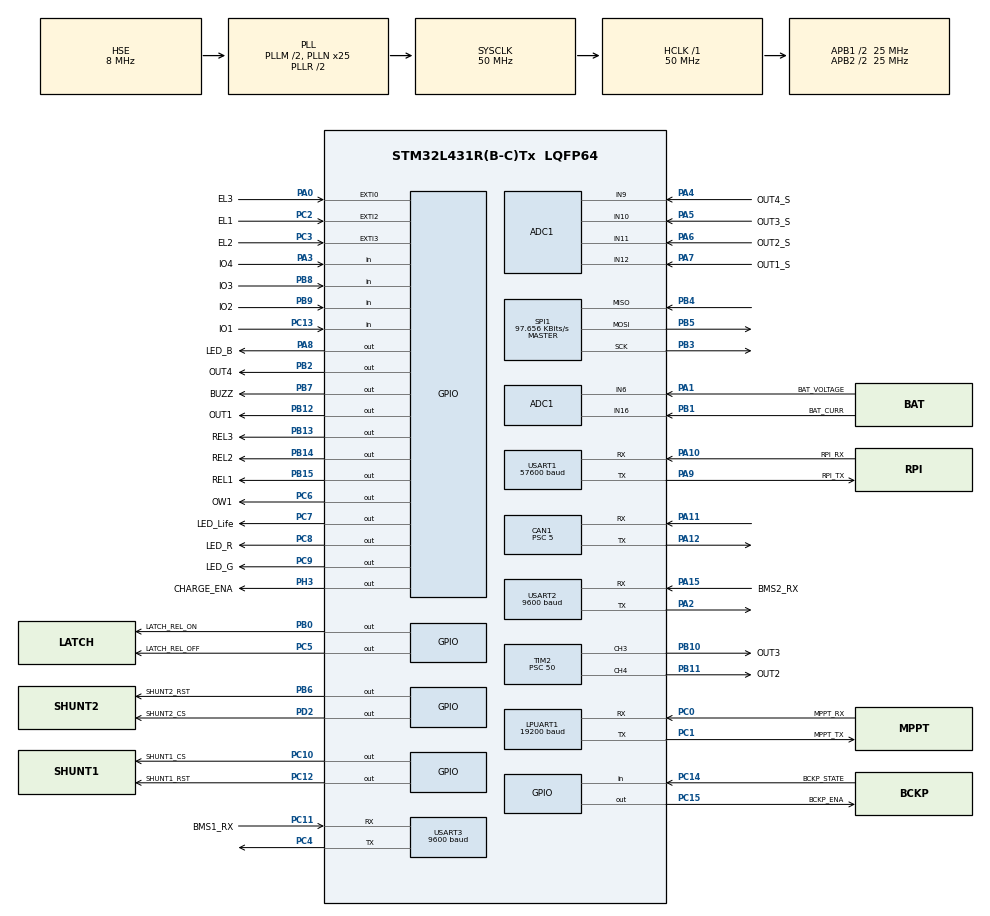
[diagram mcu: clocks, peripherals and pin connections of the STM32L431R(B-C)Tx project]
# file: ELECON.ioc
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ADC1.Channel-0\#ChannelRegularConversion=ADC_CHANNEL_6
ADC1.Channel-1\#ChannelRegularConversion=ADC_CHANNEL_9
ADC1.Channel-2\#ChannelRegularConversion=ADC_CHANNEL_10
ADC1.Channel-3\#ChannelRegularConversion=ADC_CHANNEL_11
ADC1.Channel-4\#ChannelRegularConversion=ADC_CHANNEL_12
ADC1.Channel-5\#ChannelRegularConversion=ADC_CHANNEL_16
ADC1.ContinuousConvMode=ENABLE
ADC1.DMAContinuousRequests=ENABLE
ADC1.EOCSelection=ADC_EOC_SINGLE_CONV
ADC1.NbrOfConversion=6
ADC1.NbrOfConversionFlag=1
ADC1.OffsetNumber-0\#ChannelRegularConversion=ADC_OFFSET_NONE
ADC1.OffsetNumber-1\#ChannelRegularConversion=ADC_OFFSET_NONE
ADC1.OffsetNumber-2\#ChannelRegularConversion=ADC_OFFSET_NONE
ADC1.OffsetNumber-3\#ChannelRegularConversion=ADC_OFFSET_NONE
ADC1.OffsetNumber-4\#ChannelRegularConversion=ADC_OFFSET_NONE
ADC1.OffsetNumber-5\#ChannelRegularConversion=ADC_OFFSET_NONE
ADC1.Rank-0\#ChannelRegularConversion=1
ADC1.Rank-1\#ChannelRegularConversion=2
ADC1.Rank-2\#ChannelRegularConversion=3
ADC1.Rank-3\#ChannelRegularConversion=4
ADC1.Rank-4\#ChannelRegularConversion=5
ADC1.Rank-5\#ChannelRegularConversion=6
ADC1.SamplingTime-0\#ChannelRegularConversion=ADC_SAMPLETIME_2CYCLES_5
ADC1.SamplingTime-1\#ChannelRegularConversion=ADC_SAMPLETIME_2CYCLES_5
ADC1.SamplingTime-2\#ChannelRegularConversion=ADC_SAMPLETIME_2CYCLES_5
ADC1.SamplingTime-3\#ChannelRegularConversion=ADC_SAMPLETIME_2CYCLES_5
ADC1.SamplingTime-4\#ChannelRegularConversion=ADC_SAMPLETIME_2CYCLES_5
ADC1.SamplingTime-5\#ChannelRegularConversion=ADC_SAMPLETIME_2CYCLES_5
ADC1.master=1
CAN1.ABOM=ENABLE
CAN1.BS1=CAN_BS1_15TQ
CAN1.BS2=CAN_BS2_4TQ
CAN1.CalculateBaudRate=250000
CAN1.CalculateTimeBit=4000
CAN1.CalculateTimeQuantum=200.0
CAN1.NART=ENABLE
CAN1.Prescaler=5
Dma.ADC1.2.Direction=DMA_PERIPH_TO_MEMORY
Dma.ADC1.2.Instance=DMA1_Channel1
Dma.ADC1.2.MemDataAlignment=DMA_MDATAALIGN_HALFWORD
Dma.ADC1.2.MemInc=DMA_MINC_ENABLE
Dma.ADC1.2.Mode=DMA_NORMAL
Dma.ADC1.2.PeriphDataAlignment=DMA_PDATAALIGN_HALFWORD
Dma.ADC1.2.PeriphInc=DMA_PINC_DISABLE
Dma.ADC1.2.Priority=DMA_PRIORITY_LOW
Dma.LPUART_RX.5.Direction=DMA_PERIPH_TO_MEMORY
Dma.LPUART_RX.5.Instance=DMA2_Channel7
Dma.LPUART_RX.5.MemDataAlignment=DMA_MDATAALIGN_BYTE
Dma.LPUART_RX.5.MemInc=DMA_MINC_ENABLE
Dma.LPUART_RX.5.Mode=DMA_NORMAL
Dma.LPUART_RX.5.PeriphDataAlignment=DMA_PDATAALIGN_BYTE
Dma.LPUART_RX.5.PeriphInc=DMA_PINC_DISABLE
Dma.LPUART_RX.5.Priority=DMA_PRIORITY_LOW
Dma.LPUART_TX.6.Direction=DMA_MEMORY_TO_PERIPH
Dma.LPUART_TX.6.Instance=DMA2_Channel6
Dma.LPUART_TX.6.MemDataAlignment=DMA_MDATAALIGN_BYTE
Dma.LPUART_TX.6.MemInc=DMA_MINC_ENABLE
Dma.LPUART_TX.6.Mode=DMA_NORMAL
Dma.LPUART_TX.6.PeriphDataAlignment=DMA_PDATAALIGN_BYTE
Dma.LPUART_TX.6.PeriphInc=DMA_PINC_DISABLE
Dma.LPUART_TX.6.Priority=DMA_PRIORITY_LOW
Dma.Request0=USART1_RX
Dma.Request1=USART1_TX
Dma.Request2=ADC1
Dma.Request3=USART3_RX
Dma.Request4=USART2_RX
Dma.Request5=LPUART_RX
Dma.Request6=LPUART_TX
Dma.Request7=SPI1_RX
Dma.Request8=SPI1_TX
Dma.SPI1_RX.7.Direction=DMA_PERIPH_TO_MEMORY
Dma.SPI1_RX.7.Instance=DMA1_Channel2
Dma.SPI1_RX.7.MemDataAlignment=DMA_MDATAALIGN_BYTE
Dma.SPI1_RX.7.MemInc=DMA_MINC_ENABLE
Dma.SPI1_RX.7.Mode=DMA_NORMAL
Dma.SPI1_RX.7.PeriphDataAlignment=DMA_PDATAALIGN_BYTE
Dma.SPI1_RX.7.PeriphInc=DMA_PINC_DISABLE
Dma.SPI1_RX.7.Priority=DMA_PRIORITY_LOW
Dma.SPI1_TX.8.Direction=DMA_MEMORY_TO_PERIPH
Dma.SPI1_TX.8.Instance=DMA2_Channel4
Dma.SPI1_TX.8.MemDataAlignment=DMA_MDATAALIGN_BYTE
Dma.SPI1_TX.8.MemInc=DMA_MINC_ENABLE
Dma.SPI1_TX.8.Mode=DMA_NORMAL
Dma.SPI1_TX.8.PeriphDataAlignment=DMA_PDATAALIGN_BYTE
Dma.SPI1_TX.8.PeriphInc=DMA_PINC_DISABLE
Dma.SPI1_TX.8.Priority=DMA_PRIORITY_LOW
Dma.USART1_RX.0.Direction=DMA_PERIPH_TO_MEMORY
Dma.USART1_RX.0.Instance=DMA1_Channel5
Dma.USART1_RX.0.MemDataAlignment=DMA_MDATAALIGN_BYTE
Dma.USART1_RX.0.MemInc=DMA_MINC_ENABLE
Dma.USART1_RX.0.Mode=DMA_NORMAL
Dma.USART1_RX.0.PeriphDataAlignment=DMA_PDATAALIGN_BYTE
Dma.USART1_RX.0.PeriphInc=DMA_PINC_DISABLE
Dma.USART1_RX.0.Priority=DMA_PRIORITY_LOW
Dma.USART1_TX.1.Direction=DMA_MEMORY_TO_PERIPH
Dma.USART1_TX.1.Instance=DMA1_Channel4
Dma.USART1_TX.1.MemDataAlignment=DMA_MDATAALIGN_BYTE
Dma.USART1_TX.1.MemInc=DMA_MINC_ENABLE
Dma.USART1_TX.1.Mode=DMA_NORMAL
Dma.USART1_TX.1.PeriphDataAlignment=DMA_PDATAALIGN_BYTE
Dma.USART1_TX.1.PeriphInc=DMA_PINC_DISABLE
Dma.USART1_TX.1.Priority=DMA_PRIORITY_LOW
Dma.USART2_RX.4.Direction=DMA_PERIPH_TO_MEMORY
Dma.USART2_RX.4.Instance=DMA1_Channel6
Dma.USART2_RX.4.MemDataAlignment=DMA_MDATAALIGN_BYTE
Dma.USART2_RX.4.MemInc=DMA_MINC_ENABLE
Dma.USART2_RX.4.Mode=DMA_NORMAL
Dma.USART2_RX.4.PeriphDataAlignment=DMA_PDATAALIGN_BYTE
Dma.USART2_RX.4.PeriphInc=DMA_PINC_DISABLE
Dma.USART2_RX.4.Priority=DMA_PRIORITY_LOW
Dma.USART3_RX.3.Direction=DMA_PERIPH_TO_MEMORY
Dma.USART3_RX.3.Instance=DMA1_Channel3
Dma.USART3_RX.3.MemDataAlignment=DMA_MDATAALIGN_BYTE
Dma.USART3_RX.3.MemInc=DMA_MINC_ENABLE
Dma.USART3_RX.3.Mode=DMA_NORMAL
Dma.USART3_RX.3.PeriphDataAlignment=DMA_PDATAALIGN_BYTE
Dma.USART3_RX.3.PeriphInc=DMA_PINC_DISABLE
Dma.USART3_RX.3.Priority=DMA_PRIORITY_LOW
IWDG.Prescaler=IWDG_PRESCALER_256
IWDG.Reload=375
LPUART1.BaudRate=19200
LPUART1.OverrunDisableParam=UART_ADVFEATURE_OVERRUN_DISABLE
LPUART1.WordLength=UART_WORDLENGTH_8B
Mcu.Family=STM32L4
Mcu.Name=STM32L431R(B-C)Tx
Mcu.Package=LQFP64
NVIC.ADC1_IRQn=true\:2\:0\:true\:false\:true\:true\:true\:true
NVIC.CAN1_RX0_IRQn=true\:1\:0\:true\:false\:true\:true\:true\:true
NVIC.CAN1_RX1_IRQn=true\:1\:0\:true\:false\:true\:true\:true\:true
NVIC.CAN1_TX_IRQn=true\:2\:0\:true\:false\:true\:true\:true\:true
NVIC.DMA1_Channel1_IRQn=true\:2\:0\:true\:false\:true\:false\:true\:true
NVIC.DMA1_Channel2_IRQn=true\:1\:0\:true\:false\:true\:false\:true\:true
NVIC.DMA1_Channel3_IRQn=true\:4\:0\:true\:false\:true\:false\:true\:true
NVIC.DMA1_Channel4_IRQn=true\:2\:0\:true\:false\:true\:false\:true\:true
NVIC.DMA1_Channel5_IRQn=true\:2\:0\:true\:false\:true\:false\:true\:true
NVIC.DMA1_Channel6_IRQn=true\:4\:0\:true\:false\:true\:false\:true\:true
NVIC.DMA2_Channel4_IRQn=true\:1\:0\:true\:false\:true\:false\:true\:true
NVIC.DMA2_Channel6_IRQn=true\:2\:0\:true\:false\:true\:false\:true\:true
NVIC.DMA2_Channel7_IRQn=true\:2\:0\:true\:false\:true\:false\:true\:true
NVIC.EXTI0_IRQn=true\:6\:0\:true\:false\:true\:true\:true\:true
NVIC.EXTI2_IRQn=true\:6\:0\:true\:false\:true\:true\:true\:true
NVIC.EXTI3_IRQn=true\:6\:0\:true\:false\:true\:true\:true\:true
NVIC.LPUART1_IRQn=true\:2\:0\:true\:false\:true\:true\:true\:true
NVIC.PriorityGroup=NVIC_PRIORITYGROUP_4
NVIC.SPI1_IRQn=true\:1\:0\:true\:false\:true\:true\:true\:true
NVIC.TIM6_DAC_IRQn=true\:0\:0\:false\:false\:true\:true\:true\:true
NVIC.USART1_IRQn=true\:2\:0\:true\:false\:true\:true\:true\:true
NVIC.USART2_IRQn=true\:3\:0\:true\:false\:true\:true\:true\:true
NVIC.USART3_IRQn=true\:3\:0\:true\:false\:true\:true\:true\:true
PA0.GPIO_Label=EL3
PA0.Signal=GPXTI0
PA1.GPIO_Label=BAT_VOLTAGE
PA1.Signal=ADCx_IN6
PA10.GPIO_Label=RPI_RX
PA10.Mode=Asynchronous
PA10.Signal=USART1_RX
PA11.Mode=CAN_Activate
PA11.Signal=CAN1_RX
PA12.Mode=CAN_Activate
PA12.Signal=CAN1_TX
PA13\ (JTMS-SWDIO).Mode=Serial_Wire
PA13\ (JTMS-SWDIO).Signal=SYS_JTMS-SWDIO
PA14\ (JTCK-SWCLK).Mode=Serial_Wire
PA14\ (JTCK-SWCLK).Signal=SYS_JTCK-SWCLK
PA15\ (JTDI).GPIO_Label=BMS2_RX
PA15\ (JTDI).Mode=Asynchronous
PA15\ (JTDI).Signal=USART2_RX
PA2.Mode=Asynchronous
PA2.Signal=USART2_TX
PA3.GPIO_Label=IO4
PA3.Signal=GPIO_Input
PA4.GPIO_Label=OUT4_S
PA4.Signal=ADCx_IN9
PA5.GPIO_Label=OUT3_S
PA5.Signal=ADCx_IN10
PA6.GPIO_Label=OUT2_S
PA6.Signal=ADCx_IN11
PA7.GPIO_Label=OUT1_S
PA7.Signal=ADCx_IN12
PA8.GPIO_Label=LED_B
PA8.Signal=GPIO_Output
PA9.GPIO_Label=RPI_TX
PA9.Mode=Asynchronous
PA9.Signal=USART1_TX
PB0.GPIO_Label=LATCH_REL_ON
PB0.Signal=GPIO_Output
PB1.GPIO_Label=BAT_CURR
PB1.Signal=ADCx_IN16
PB10.GPIO_Label=OUT3
PB10.Signal=S_TIM2_CH3
PB11.GPIO_Label=OUT2
PB11.Signal=S_TIM2_CH4
PB12.GPIO_Label=OUT1
PB12.Signal=GPIO_Output
PB13.GPIO_Label=REL3
PB13.Signal=GPIO_Output
PB14.GPIO_Label=REL2
PB14.Signal=GPIO_Output
PB15.GPIO_Label=REL1
PB15.Signal=GPIO_Output
PB2.GPIO_Label=OUT4
PB2.Signal=GPIO_Output
PB3\ (JTDO-TRACESWO).Mode=Full_Duplex_Master
PB3\ (JTDO-TRACESWO).Signal=SPI1_SCK
PB4\ (NJTRST).Mode=Full_Duplex_Master
PB4\ (NJTRST).Signal=SPI1_MISO
PB5.Mode=Full_Duplex_Master
PB5.Signal=SPI1_MOSI
PB6.GPIO_Label=SHUNT2_RST
PB6.Signal=GPIO_Output
PB7.GPIO_Label=BUZZ
PB7.Signal=GPIO_Output
PB8.GPIO_Label=IO3
PB8.Signal=GPIO_Input
PB9.GPIO_Label=IO2
PB9.Signal=GPIO_Input
PC0.GPIO_Label=MPPT_RX
PC0.Mode=Asynchronous
PC0.Signal=LPUART1_RX
PC1.GPIO_Label=MPPT_TX
PC1.Mode=Asynchronous
PC1.Signal=LPUART1_TX
PC10.GPIO_Label=SHUNT1_CS
PC10.Signal=GPIO_Output
PC11.GPIO_Label=BMS1_RX
PC11.Mode=Asynchronous
PC11.Signal=USART3_RX
PC12.GPIO_Label=SHUNT1_RST
PC12.Signal=GPIO_Output
PC13.GPIO_Label=IO1
PC13.Signal=GPIO_Input
PC14-OSC32_IN\ (PC14).GPIO_Label=BCKP_STATE
PC14-OSC32_IN\ (PC14).GPIO_PuPd=GPIO_PULLDOWN
PC14-OSC32_IN\ (PC14).Signal=GPIO_Input
PC15-OSC32_OUT\ (PC15).GPIO_Label=BCKP_ENA
PC15-OSC32_OUT\ (PC15).Signal=GPIO_Output
PC2.GPIO_Label=EL1
PC2.Signal=GPXTI2
PC3.GPIO_Label=EL2
PC3.Signal=GPXTI3
PC4.Mode=Asynchronous
PC4.Signal=USART3_TX
PC5.GPIO_Label=LATCH_REL_OFF
PC5.Signal=GPIO_Output
PC6.GPIO_Label=OW1
PC6.GPIO_ModeDefaultOutputPP=GPIO_MODE_OUTPUT_OD
PC6.Signal=GPIO_Output
PC7.GPIO_Label=LED_Life
PC7.Signal=GPIO_Output
PC8.GPIO_Label=LED_R
PC8.Signal=GPIO_Output
PC9.GPIO_Label=LED_G
PC9.Signal=GPIO_Output
PD2.GPIO_Label=SHUNT2_CS
PD2.Signal=GPIO_Output
PH0-OSC_IN\ (PH0).Mode=HSE-External-Oscillator
PH0-OSC_IN\ (PH0).Signal=RCC_OSC_IN
PH1-OSC_OUT\ (PH1).Mode=HSE-External-Oscillator
PH1-OSC_OUT\ (PH1).Signal=RCC_OSC_OUT
PH3-BOOT0.GPIO_Label=CHARGE_ENA
PH3-BOOT0.Signal=GPIO_Output
ProjectManager.HeapSize=0x2000
ProjectManager.StackSize=0x400
ProjectManager.TargetToolchain=STM32CubeIDE
RCC.ADCCLockSelection=RCC_ADCCLKSOURCE_SYSCLK
RCC.ADCFreq_Value=50000000
RCC.AHBFreq_Value=50000000
RCC.APB1CLKDivider=RCC_HCLK_DIV2
RCC.APB1Freq_Value=25000000
RCC.APB1TimFreq_Value=50000000
RCC.APB2CLKDivider=RCC_HCLK_DIV2
RCC.APB2Freq_Value=25000000
RCC.APB2TimFreq_Value=50000000
RCC.CortexFreq_Value=50000000
RCC.HCLKFreq_Value=50000000
RCC.HSE_VALUE=8000000
RCC.HSI48_VALUE=48000000
RCC.HSI_VALUE=16000000
RCC.LSE_VALUE=32768
RCC.MSI_VALUE=4000000
RCC.PLLM=2
RCC.PLLN=25
RCC.PLLSAI1N=26
RCC.PLLSourceVirtual=RCC_PLLSOURCE_HSE
RCC.RTCClockSelection=RCC_RTCCLKSOURCE_HSE_DIV32
RCC.SYSCLKFreq_VALUE=50000000
RCC.SYSCLKSource=RCC_SYSCLKSOURCE_PLLCLK
RCC.VCOOutputFreq_Value=100000000
RTC.AsynchPrediv=124
RTC.SynchPrediv=1999
SH.ADCx_IN10.0=ADC1_IN10,IN10-Single-Ended
SH.ADCx_IN11.0=ADC1_IN11,IN11-Single-Ended
SH.ADCx_IN12.0=ADC1_IN12,IN12-Single-Ended
SH.ADCx_IN16.0=ADC1_IN16,IN16-Single-Ended
SH.ADCx_IN6.0=ADC1_IN6,IN6-Single-Ended
SH.ADCx_IN9.0=ADC1_IN9,IN9-Single-Ended
SH.S_TIM2_CH3.0=TIM2_CH3,PWM Generation3 CH3
SH.S_TIM2_CH4.0=TIM2_CH4,PWM Generation4 CH4
SPI1.BaudRatePrescaler=SPI_BAUDRATEPRESCALER_256
SPI1.CLKPhase=SPI_PHASE_2EDGE
SPI1.CalculateBaudRate=97.656 KBits/s
SPI1.DataSize=SPI_DATASIZE_8BIT
SPI1.Direction=SPI_DIRECTION_2LINES
SPI1.Mode=SPI_MODE_MASTER
SPI1.VirtualType=VM_MASTER
TIM2.Channel-PWM\ Generation3\ CH3=TIM_CHANNEL_3
TIM2.Channel-PWM\ Generation4\ CH4=TIM_CHANNEL_4
TIM2.Period=1000
TIM2.Prescaler=50
TIM6.Period=1000
TIM6.Prescaler=4
USART1.BaudRate=57600
USART1.VirtualMode-Asynchronous=VM_ASYNC
USART2.BaudRate=9600
USART2.Mode=MODE_RX
USART2.OverrunDisableParam=ADVFEATURE_OVERRUN_DISABLE
USART2.VirtualMode-Asynchronous=VM_ASYNC
USART3.BaudRate=9600
USART3.Mode=MODE_RX
USART3.OverrunDisableParam=ADVFEATURE_OVERRUN_DISABLE
USART3.VirtualMode-Asynchronous=VM_ASYNC
VP_IWDG_VS_IWDG.Mode=IWDG_Activate
VP_RTC_VS_RTC_Activate.Mode=RTC_Enabled
VP_TIM2_VS_ClockSourceINT.Mode=Internal
VP_TIM6_VS_ClockSourceINT.Mode=Enable_Timer
board=custom

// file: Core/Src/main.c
/* USER CODE BEGIN Header */
/**
  ******************************************************************************
  * @file           : main.c
  * @brief          : Main program body
  ******************************************************************************
  * @attention
  *
  * <h2><center>&copy; Copyright (c) 2021 STMicroelectronics.
  * All rights reserved.</center></h2>
  *
  * This software component is licensed by ST under BSD 3-Clause license,
  * the "License"; You may not use this file except in compliance with the
  * License. You may obtain a copy of the License at:
  *                        opensource.org/licenses/BSD-3-Clause
  *
  ******************************************************************************
  */
/* USER CODE END Header */
#include "main.h"

/* USER CODE BEGIN Includes */
#include "APP.h"
#include "MEMORY_MAP.h"
/* USER CODE END Includes */

 ADC_HandleTypeDef hadc1;
DMA_HandleTypeDef hdma_adc1;

CAN_HandleTypeDef hcan1;

IWDG_HandleTypeDef hiwdg;

UART_HandleTypeDef hlpuart1;
UART_HandleTypeDef huart1;
UART_HandleTypeDef huart2;
UART_HandleTypeDef huart3;
DMA_HandleTypeDef hdma_lpuart_rx;
DMA_HandleTypeDef hdma_lpuart_tx;
DMA_HandleTypeDef hdma_usart1_rx;
DMA_HandleTypeDef hdma_usart1_tx;
DMA_HandleTypeDef hdma_usart2_rx;
DMA_HandleTypeDef hdma_usart3_rx;

RTC_HandleTypeDef hrtc;

SPI_HandleTypeDef hspi1;
DMA_HandleTypeDef hdma_spi1_rx;
DMA_HandleTypeDef hdma_spi1_tx;

TIM_HandleTypeDef htim2;
TIM_HandleTypeDef htim6;

void SystemClock_Config(void);
static void MX_GPIO_Init(void);
static void MX_DMA_Init(void);
static void MX_CAN1_Init(void);
static void MX_USART1_UART_Init(void);
static void MX_TIM6_Init(void);
static void MX_ADC1_Init(void);
static void MX_RTC_Init(void);
static void MX_IWDG_Init(void);
static void MX_LPUART1_UART_Init(void);
static void MX_USART2_UART_Init(void);
static void MX_USART3_UART_Init(void);
static void MX_SPI1_Init(void);
static void MX_TIM2_Init(void);

int main(void)
{
  /* USER CODE BEGIN 1 */
  SCB->VTOR = ADDRESS_OF_DEFAULT_APP_START;
  __DSB();
  __ISB();
  __enable_irq();   // clears PRIMASK

  /* USER CODE END 1 */

  /* MCU Configuration--------------------------------------------------------*/

  /* Reset of all peripherals, Initializes the Flash interface and the Systick. */
  HAL_Init();

  /* Configure the system clock */
  SystemClock_Config();

  /* Initialize all configured peripherals */
  MX_GPIO_Init();
  MX_DMA_Init();
  MX_CAN1_Init();
  MX_USART1_UART_Init();
  MX_TIM6_Init();
  MX_ADC1_Init();
  MX_RTC_Init();
  MX_IWDG_Init();
  MX_LPUART1_UART_Init();
  MX_USART2_UART_Init();
  MX_USART3_UART_Init();
  MX_SPI1_Init();
  MX_TIM2_Init();

  /* Infinite loop */
  /* USER CODE BEGIN WHILE */

  APP_Init();
  APP_Start();

  while (1)
  {
    /* USER CODE END WHILE */

  }
}

void SystemClock_Config(void)
{
  RCC_OscInitTypeDef RCC_OscInitStruct = {0};
  RCC_ClkInitTypeDef RCC_ClkInitStruct = {0};

  /** Configure the main internal regulator output voltage
  */
  if (HAL_PWREx_ControlVoltageScaling(PWR_REGULATOR_VOLTAGE_SCALE1) != HAL_OK)
  {
    Error_Handler();
  }

  /** Initializes the RCC Oscillators according to the specified parameters
  * in the RCC_OscInitTypeDef structure.
  */
  RCC_OscInitStruct.OscillatorType = RCC_OSCILLATORTYPE_LSI|RCC_OSCILLATORTYPE_HSE;
  RCC_OscInitStruct.HSEState = RCC_HSE_ON;
  RCC_OscInitStruct.LSIState = RCC_LSI_ON;
  RCC_OscInitStruct.PLL.PLLState = RCC_PLL_ON;
  RCC_OscInitStruct.PLL.PLLSource = RCC_PLLSOURCE_HSE;
  RCC_OscInitStruct.PLL.PLLM = 2;
  RCC_OscInitStruct.PLL.PLLN = 25;
  RCC_OscInitStruct.PLL.PLLP = RCC_PLLP_DIV7;
  RCC_OscInitStruct.PLL.PLLQ = RCC_PLLQ_DIV2;
  RCC_OscInitStruct.PLL.PLLR = RCC_PLLR_DIV2;
  if (HAL_RCC_OscConfig(&RCC_OscInitStruct) != HAL_OK)
  {
    Error_Handler();
  }

  /** Initializes the CPU, AHB and APB buses clocks
  */
  RCC_ClkInitStruct.ClockType = RCC_CLOCKTYPE_HCLK|RCC_CLOCKTYPE_SYSCLK
                              |RCC_CLOCKTYPE_PCLK1|RCC_CLOCKTYPE_PCLK2;
  RCC_ClkInitStruct.SYSCLKSource = RCC_SYSCLKSOURCE_PLLCLK;
  RCC_ClkInitStruct.AHBCLKDivider = RCC_SYSCLK_DIV1;
  RCC_ClkInitStruct.APB1CLKDivider = RCC_HCLK_DIV2;
  RCC_ClkInitStruct.APB2CLKDivider = RCC_HCLK_DIV2;

  if (HAL_RCC_ClockConfig(&RCC_ClkInitStruct, FLASH_LATENCY_3) != HAL_OK)
  {
    Error_Handler();
  }
}

static void MX_ADC1_Init(void)
{

  ADC_ChannelConfTypeDef sConfig = {0};

  /** Common config
  */
  hadc1.Instance = ADC1;
  hadc1.Init.ClockPrescaler = ADC_CLOCK_ASYNC_DIV1;
  hadc1.Init.Resolution = ADC_RESOLUTION_12B;
  hadc1.Init.DataAlign = ADC_DATAALIGN_RIGHT;
  hadc1.Init.ScanConvMode = ADC_SCAN_ENABLE;
  hadc1.Init.EOCSelection = ADC_EOC_SINGLE_CONV;
  hadc1.Init.LowPowerAutoWait = DISABLE;
  hadc1.Init.ContinuousConvMode = ENABLE;
  hadc1.Init.NbrOfConversion = 6;
  hadc1.Init.DiscontinuousConvMode = DISABLE;
  hadc1.Init.ExternalTrigConv = ADC_SOFTWARE_START;
  hadc1.Init.ExternalTrigConvEdge = ADC_EXTERNALTRIGCONVEDGE_NONE;
  hadc1.Init.DMAContinuousRequests = ENABLE;
  hadc1.Init.Overrun = ADC_OVR_DATA_PRESERVED;
  hadc1.Init.OversamplingMode = DISABLE;
  if (HAL_ADC_Init(&hadc1) != HAL_OK)
  {
    Error_Handler();
  }

  /** Configure Regular Channel
  */
  sConfig.Channel = ADC_CHANNEL_6;
  sConfig.Rank = ADC_REGULAR_RANK_1;
  sConfig.SamplingTime = ADC_SAMPLETIME_2CYCLES_5;
  sConfig.SingleDiff = ADC_SINGLE_ENDED;
  sConfig.OffsetNumber = ADC_OFFSET_NONE;
  sConfig.Offset = 0;
  if (HAL_ADC_ConfigChannel(&hadc1, &sConfig) != HAL_OK)
  {
    Error_Handler();
  }

  /** Configure Regular Channel
  */
  sConfig.Channel = ADC_CHANNEL_9;
  sConfig.Rank = ADC_REGULAR_RANK_2;
  if (HAL_ADC_ConfigChannel(&hadc1, &sConfig) != HAL_OK)
  {
    Error_Handler();
  }

  /** Configure Regular Channel
  */
  sConfig.Channel = ADC_CHANNEL_10;
  sConfig.Rank = ADC_REGULAR_RANK_3;
  if (HAL_ADC_ConfigChannel(&hadc1, &sConfig) != HAL_OK)
  {
    Error_Handler();
  }

  /** Configure Regular Channel
  */
  sConfig.Channel = ADC_CHANNEL_11;
  sConfig.Rank = ADC_REGULAR_RANK_4;
  if (HAL_ADC_ConfigChannel(&hadc1, &sConfig) != HAL_OK)
  {
    Error_Handler();
  }

  /** Configure Regular Channel
  */
  sConfig.Channel = ADC_CHANNEL_12;
  sConfig.Rank = ADC_REGULAR_RANK_5;
  if (HAL_ADC_ConfigChannel(&hadc1, &sConfig) != HAL_OK)
  {
    Error_Handler();
  }

  /** Configure Regular Channel
  */
  sConfig.Channel = ADC_CHANNEL_16;
  sConfig.Rank = ADC_REGULAR_RANK_6;
  if (HAL_ADC_ConfigChannel(&hadc1, &sConfig) != HAL_OK)
  {
    Error_Handler();
  }

}

static void MX_CAN1_Init(void)
{

  hcan1.Instance = CAN1;
  hcan1.Init.Prescaler = 5;
  hcan1.Init.Mode = CAN_MODE_NORMAL;
  hcan1.Init.SyncJumpWidth = CAN_SJW_1TQ;
  hcan1.Init.TimeSeg1 = CAN_BS1_15TQ;
  hcan1.Init.TimeSeg2 = CAN_BS2_4TQ;
  hcan1.Init.TimeTriggeredMode = DISABLE;
  hcan1.Init.AutoBusOff = ENABLE;
  hcan1.Init.AutoWakeUp = DISABLE;
  hcan1.Init.AutoRetransmission = ENABLE;
  hcan1.Init.ReceiveFifoLocked = DISABLE;
  hcan1.Init.TransmitFifoPriority = DISABLE;
  if (HAL_CAN_Init(&hcan1) != HAL_OK)
  {
    Error_Handler();
  }

}

static void MX_IWDG_Init(void)
{

  hiwdg.Instance = IWDG;
  hiwdg.Init.Prescaler = IWDG_PRESCALER_256;
  hiwdg.Init.Window = 4095;
  hiwdg.Init.Reload = 375;
  if (HAL_IWDG_Init(&hiwdg) != HAL_OK)
  {
    Error_Handler();
  }

}

static void MX_LPUART1_UART_Init(void)
{

  hlpuart1.Instance = LPUART1;
  hlpuart1.Init.BaudRate = 19200;
  hlpuart1.Init.WordLength = UART_WORDLENGTH_8B;
  hlpuart1.Init.StopBits = UART_STOPBITS_1;
  hlpuart1.Init.Parity = UART_PARITY_NONE;
  hlpuart1.Init.Mode = UART_MODE_TX_RX;
  hlpuart1.Init.HwFlowCtl = UART_HWCONTROL_NONE;
  hlpuart1.Init.OneBitSampling = UART_ONE_BIT_SAMPLE_DISABLE;
  hlpuart1.AdvancedInit.AdvFeatureInit = UART_ADVFEATURE_RXOVERRUNDISABLE_INIT;
  hlpuart1.AdvancedInit.OverrunDisable = UART_ADVFEATURE_OVERRUN_DISABLE;
  if (HAL_UART_Init(&hlpuart1) != HAL_OK)
  {
    Error_Handler();
  }

}

static void MX_USART1_UART_Init(void)
{

  huart1.Instance = USART1;
  huart1.Init.BaudRate = 115200;
  huart1.Init.WordLength = UART_WORDLENGTH_8B;
  huart1.Init.StopBits = UART_STOPBITS_1;
  huart1.Init.Parity = UART_PARITY_NONE;
  huart1.Init.Mode = UART_MODE_TX_RX;
  huart1.Init.HwFlowCtl = UART_HWCONTROL_NONE;
  huart1.Init.OverSampling = UART_OVERSAMPLING_16;
  huart1.Init.OneBitSampling = UART_ONE_BIT_SAMPLE_DISABLE;
  huart1.AdvancedInit.AdvFeatureInit = UART_ADVFEATURE_NO_INIT;
  if (HAL_UART_Init(&huart1) != HAL_OK)
  {
    Error_Handler();
  }

}

static void MX_USART2_UART_Init(void)
{

  huart2.Instance = USART2;
  huart2.Init.BaudRate = 9600;
  huart2.Init.WordLength = UART_WORDLENGTH_8B;
  huart2.Init.StopBits = UART_STOPBITS_1;
  huart2.Init.Parity = UART_PARITY_NONE;
  huart2.Init.Mode = UART_MODE_RX;
  huart2.Init.HwFlowCtl = UART_HWCONTROL_NONE;
  huart2.Init.OverSampling = UART_OVERSAMPLING_16;
  huart2.Init.OneBitSampling = UART_ONE_BIT_SAMPLE_DISABLE;
  huart2.AdvancedInit.AdvFeatureInit = UART_ADVFEATURE_RXOVERRUNDISABLE_INIT;
  huart2.AdvancedInit.OverrunDisable = UART_ADVFEATURE_OVERRUN_DISABLE;
  if (HAL_UART_Init(&huart2) != HAL_OK)
  {
    Error_Handler();
  }

}

static void MX_USART3_UART_Init(void)
{

  huart3.Instance = USART3;
  huart3.Init.BaudRate = 9600;
  huart3.Init.WordLength = UART_WORDLENGTH_8B;
  huart3.Init.StopBits = UART_STOPBITS_1;
  huart3.Init.Parity = UART_PARITY_NONE;
  huart3.Init.Mode = UART_MODE_RX;
  huart3.Init.HwFlowCtl = UART_HWCONTROL_NONE;
  huart3.Init.OverSampling = UART_OVERSAMPLING_16;
  huart3.Init.OneBitSampling = UART_ONE_BIT_SAMPLE_DISABLE;
  huart3.AdvancedInit.AdvFeatureInit = UART_ADVFEATURE_RXOVERRUNDISABLE_INIT;
  huart3.AdvancedInit.OverrunDisable = UART_ADVFEATURE_OVERRUN_DISABLE;
  if (HAL_UART_Init(&huart3) != HAL_OK)
  {
    Error_Handler();
  }

}

static void MX_RTC_Init(void)
{

  /** Initialize RTC Only
  */
  hrtc.Instance = RTC;
  hrtc.Init.HourFormat = RTC_HOURFORMAT_24;
  hrtc.Init.AsynchPrediv = 124;
  hrtc.Init.SynchPrediv = 1999;
  hrtc.Init.OutPut = RTC_OUTPUT_DISABLE;
  hrtc.Init.OutPutRemap = RTC_OUTPUT_REMAP_NONE;
  hrtc.Init.OutPutPolarity = RTC_OUTPUT_POLARITY_HIGH;
  hrtc.Init.OutPutType = RTC_OUTPUT_TYPE_OPENDRAIN;
  if (HAL_RTC_Init(&hrtc) != HAL_OK)
  {
    Error_Handler();
  }

}

static void MX_SPI1_Init(void)
{

  /* SPI1 parameter configuration*/
  hspi1.Instance = SPI1;
  hspi1.Init.Mode = SPI_MODE_MASTER;
  hspi1.Init.Direction = SPI_DIRECTION_2LINES;
  hspi1.Init.DataSize = SPI_DATASIZE_8BIT;
  hspi1.Init.CLKPolarity = SPI_POLARITY_LOW;
  hspi1.Init.CLKPhase = SPI_PHASE_2EDGE;
  hspi1.Init.NSS = SPI_NSS_SOFT;
  hspi1.Init.BaudRatePrescaler = SPI_BAUDRATEPRESCALER_256;
  hspi1.Init.FirstBit = SPI_FIRSTBIT_MSB;
  hspi1.Init.TIMode = SPI_TIMODE_DISABLE;
  hspi1.Init.CRCCalculation = SPI_CRCCALCULATION_DISABLE;
  hspi1.Init.CRCPolynomial = 7;
  hspi1.Init.CRCLength = SPI_CRC_LENGTH_DATASIZE;
  hspi1.Init.NSSPMode = SPI_NSS_PULSE_DISABLE;
  if (HAL_SPI_Init(&hspi1) != HAL_OK)
  {
    Error_Handler();
  }

}

static void MX_TIM2_Init(void)
{

  TIM_ClockConfigTypeDef sClockSourceConfig = {0};
  TIM_MasterConfigTypeDef sMasterConfig = {0};
  TIM_OC_InitTypeDef sConfigOC = {0};

  htim2.Instance = TIM2;
  htim2.Init.Prescaler = 50;
  htim2.Init.CounterMode = TIM_COUNTERMODE_UP;
  htim2.Init.Period = 1000;
  htim2.Init.ClockDivision = TIM_CLOCKDIVISION_DIV1;
  htim2.Init.AutoReloadPreload = TIM_AUTORELOAD_PRELOAD_DISABLE;
  if (HAL_TIM_Base_Init(&htim2) != HAL_OK)
  {
    Error_Handler();
  }
  sClockSourceConfig.ClockSource = TIM_CLOCKSOURCE_INTERNAL;
  if (HAL_TIM_ConfigClockSource(&htim2, &sClockSourceConfig) != HAL_OK)
  {
    Error_Handler();
  }
  if (HAL_TIM_PWM_Init(&htim2) != HAL_OK)
  {
    Error_Handler();
  }
  sMasterConfig.MasterOutputTrigger = TIM_TRGO_RESET;
  sMasterConfig.MasterSlaveMode = TIM_MASTERSLAVEMODE_DISABLE;
  if (HAL_TIMEx_MasterConfigSynchronization(&htim2, &sMasterConfig) != HAL_OK)
  {
    Error_Handler();
  }
  sConfigOC.OCMode = TIM_OCMODE_PWM1;
  sConfigOC.Pulse = 0;
  sConfigOC.OCPolarity = TIM_OCPOLARITY_HIGH;
  sConfigOC.OCFastMode = TIM_OCFAST_DISABLE;
  if (HAL_TIM_PWM_ConfigChannel(&htim2, &sConfigOC, TIM_CHANNEL_3) != HAL_OK)
  {
    Error_Handler();
  }
  if (HAL_TIM_PWM_ConfigChannel(&htim2, &sConfigOC, TIM_CHANNEL_4) != HAL_OK)
  {
    Error_Handler();
  }
  HAL_TIM_MspPostInit(&htim2);

}

static void MX_TIM6_Init(void)
{

  TIM_MasterConfigTypeDef sMasterConfig = {0};

  htim6.Instance = TIM6;
  htim6.Init.Prescaler = 4;
  htim6.Init.CounterMode = TIM_COUNTERMODE_UP;
  htim6.Init.Period = 1000;
  htim6.Init.AutoReloadPreload = TIM_AUTORELOAD_PRELOAD_DISABLE;
  if (HAL_TIM_Base_Init(&htim6) != HAL_OK)
  {
    Error_Handler();
  }
  sMasterConfig.MasterOutputTrigger = TIM_TRGO_RESET;
  sMasterConfig.MasterSlaveMode = TIM_MASTERSLAVEMODE_DISABLE;
  if (HAL_TIMEx_MasterConfigSynchronization(&htim6, &sMasterConfig) != HAL_OK)
  {
    Error_Handler();
  }

}

static void MX_DMA_Init(void)
{

  /* DMA controller clock enable */
  __HAL_RCC_DMA1_CLK_ENABLE();
  __HAL_RCC_DMA2_CLK_ENABLE();

  /* DMA interrupt init */
  /* DMA1_Channel1_IRQn interrupt configuration */
  HAL_NVIC_SetPriority(DMA1_Channel1_IRQn, 2, 0);
  HAL_NVIC_EnableIRQ(DMA1_Channel1_IRQn);
  /* DMA1_Channel2_IRQn interrupt configuration */
  HAL_NVIC_SetPriority(DMA1_Channel2_IRQn, 1, 0);
  HAL_NVIC_EnableIRQ(DMA1_Channel2_IRQn);
  /* DMA1_Channel3_IRQn interrupt configuration */
  HAL_NVIC_SetPriority(DMA1_Channel3_IRQn, 4, 0);
  HAL_NVIC_EnableIRQ(DMA1_Channel3_IRQn);
  /* DMA1_Channel4_IRQn interrupt configuration */
  HAL_NVIC_SetPriority(DMA1_Channel4_IRQn, 2, 0);
  HAL_NVIC_EnableIRQ(DMA1_Channel4_IRQn);
  /* DMA1_Channel5_IRQn interrupt configuration */
  HAL_NVIC_SetPriority(DMA1_Channel5_IRQn, 2, 0);
  HAL_NVIC_EnableIRQ(DMA1_Channel5_IRQn);
  /* DMA1_Channel6_IRQn interrupt configuration */
  HAL_NVIC_SetPriority(DMA1_Channel6_IRQn, 4, 0);
  HAL_NVIC_EnableIRQ(DMA1_Channel6_IRQn);
  /* DMA2_Channel4_IRQn interrupt configuration */
  HAL_NVIC_SetPriority(DMA2_Channel4_IRQn, 1, 0);
  HAL_NVIC_EnableIRQ(DMA2_Channel4_IRQn);
  /* DMA2_Channel6_IRQn interrupt configuration */
  HAL_NVIC_SetPriority(DMA2_Channel6_IRQn, 2, 0);
  HAL_NVIC_EnableIRQ(DMA2_Channel6_IRQn);
  /* DMA2_Channel7_IRQn interrupt configuration */
  HAL_NVIC_SetPriority(DMA2_Channel7_IRQn, 2, 0);
  HAL_NVIC_EnableIRQ(DMA2_Channel7_IRQn);

}

static void MX_GPIO_Init(void)
{
  GPIO_InitTypeDef GPIO_InitStruct = {0};

  /* GPIO Ports Clock Enable */
  __HAL_RCC_GPIOC_CLK_ENABLE();
  __HAL_RCC_GPIOH_CLK_ENABLE();
  __HAL_RCC_GPIOA_CLK_ENABLE();
  __HAL_RCC_GPIOB_CLK_ENABLE();
  __HAL_RCC_GPIOD_CLK_ENABLE();

  /*Configure GPIO pin Output Level */
  HAL_GPIO_WritePin(GPIOC, BCKP_ENA_Pin|LATCH_REL_OFF_Pin|OW1_Pin|LED_Life_Pin
                          |LED_R_Pin|LED_G_Pin|SHUNT1_CS_Pin|SHUNT1_RST_Pin, GPIO_PIN_RESET);

  /*Configure GPIO pin Output Level */
  HAL_GPIO_WritePin(GPIOB, LATCH_REL_ON_Pin|OUT4_Pin|OUT1_Pin|REL3_Pin
                          |REL2_Pin|REL1_Pin|SHUNT2_RST_Pin|BUZZ_Pin, GPIO_PIN_RESET);

  /*Configure GPIO pin Output Level */
  HAL_GPIO_WritePin(LED_B_GPIO_Port, LED_B_Pin, GPIO_PIN_RESET);

  /*Configure GPIO pin Output Level */
  HAL_GPIO_WritePin(SHUNT2_CS_GPIO_Port, SHUNT2_CS_Pin, GPIO_PIN_RESET);

  /*Configure GPIO pin Output Level */
  HAL_GPIO_WritePin(CHARGE_ENA_GPIO_Port, CHARGE_ENA_Pin, GPIO_PIN_RESET);

  /*Configure GPIO pin : IO1_Pin */
  GPIO_InitStruct.Pin = IO1_Pin;
  GPIO_InitStruct.Mode = GPIO_MODE_INPUT;
  GPIO_InitStruct.Pull = GPIO_NOPULL;
  HAL_GPIO_Init(IO1_GPIO_Port, &GPIO_InitStruct);

  /*Configure GPIO pin : BCKP_STATE_Pin */
  GPIO_InitStruct.Pin = BCKP_STATE_Pin;
  GPIO_InitStruct.Mode = GPIO_MODE_INPUT;
  GPIO_InitStruct.Pull = GPIO_PULLDOWN;
  HAL_GPIO_Init(BCKP_STATE_GPIO_Port, &GPIO_InitStruct);

  /*Configure GPIO pins : BCKP_ENA_Pin LATCH_REL_OFF_Pin LED_Life_Pin LED_R_Pin
                           LED_G_Pin SHUNT1_CS_Pin SHUNT1_RST_Pin */
  GPIO_InitStruct.Pin = BCKP_ENA_Pin|LATCH_REL_OFF_Pin|LED_Life_Pin|LED_R_Pin
                          |LED_G_Pin|SHUNT1_CS_Pin|SHUNT1_RST_Pin;
  GPIO_InitStruct.Mode = GPIO_MODE_OUTPUT_PP;
  GPIO_InitStruct.Pull = GPIO_NOPULL;
  GPIO_InitStruct.Speed = GPIO_SPEED_FREQ_LOW;
  HAL_GPIO_Init(GPIOC, &GPIO_InitStruct);

  /*Configure GPIO pins : EL1_Pin EL2_Pin */
  GPIO_InitStruct.Pin = EL1_Pin|EL2_Pin;
  GPIO_InitStruct.Mode = GPIO_MODE_IT_RISING;
  GPIO_InitStruct.Pull = GPIO_NOPULL;
  HAL_GPIO_Init(GPIOC, &GPIO_InitStruct);

  /*Configure GPIO pin : EL3_Pin */
  GPIO_InitStruct.Pin = EL3_Pin;
  GPIO_InitStruct.Mode = GPIO_MODE_IT_RISING;
  GPIO_InitStruct.Pull = GPIO_NOPULL;
  HAL_GPIO_Init(EL3_GPIO_Port, &GPIO_InitStruct);

  /*Configure GPIO pin : IO4_Pin */
  GPIO_InitStruct.Pin = IO4_Pin;
  GPIO_InitStruct.Mode = GPIO_MODE_INPUT;
  GPIO_InitStruct.Pull = GPIO_NOPULL;
  HAL_GPIO_Init(IO4_GPIO_Port, &GPIO_InitStruct);

  /*Configure GPIO pins : LATCH_REL_ON_Pin OUT4_Pin OUT1_Pin REL3_Pin
                           REL2_Pin REL1_Pin SHUNT2_RST_Pin BUZZ_Pin */
  GPIO_InitStruct.Pin = LATCH_REL_ON_Pin|OUT4_Pin|OUT1_Pin|REL3_Pin
                          |REL2_Pin|REL1_Pin|SHUNT2_RST_Pin|BUZZ_Pin;
  GPIO_InitStruct.Mode = GPIO_MODE_OUTPUT_PP;
  GPIO_InitStruct.Pull = GPIO_NOPULL;
  GPIO_InitStruct.Speed = GPIO_SPEED_FREQ_LOW;
  HAL_GPIO_Init(GPIOB, &GPIO_InitStruct);

  /*Configure GPIO pin : OW1_Pin */
  GPIO_InitStruct.Pin = OW1_Pin;
  GPIO_InitStruct.Mode = GPIO_MODE_OUTPUT_OD;
  GPIO_InitStruct.Pull = GPIO_NOPULL;
  GPIO_InitStruct.Speed = GPIO_SPEED_FREQ_LOW;
  HAL_GPIO_Init(OW1_GPIO_Port, &GPIO_InitStruct);

  /*Configure GPIO pin : LED_B_Pin */
  GPIO_InitStruct.Pin = LED_B_Pin;
  GPIO_InitStruct.Mode = GPIO_MODE_OUTPUT_PP;
  GPIO_InitStruct.Pull = GPIO_NOPULL;
  GPIO_InitStruct.Speed = GPIO_SPEED_FREQ_LOW;
  HAL_GPIO_Init(LED_B_GPIO_Port, &GPIO_InitStruct);

  /*Configure GPIO pin : SHUNT2_CS_Pin */
  GPIO_InitStruct.Pin = SHUNT2_CS_Pin;
  GPIO_InitStruct.Mode = GPIO_MODE_OUTPUT_PP;
  GPIO_InitStruct.Pull = GPIO_NOPULL;
  GPIO_InitStruct.Speed = GPIO_SPEED_FREQ_LOW;
  HAL_GPIO_Init(SHUNT2_CS_GPIO_Port, &GPIO_InitStruct);

  /*Configure GPIO pin : CHARGE_ENA_Pin */
  GPIO_InitStruct.Pin = CHARGE_ENA_Pin;
  GPIO_InitStruct.Mode = GPIO_MODE_OUTPUT_PP;
  GPIO_InitStruct.Pull = GPIO_NOPULL;
  GPIO_InitStruct.Speed = GPIO_SPEED_FREQ_LOW;
  HAL_GPIO_Init(CHARGE_ENA_GPIO_Port, &GPIO_InitStruct);

  /*Configure GPIO pins : IO3_Pin IO2_Pin */
  GPIO_InitStruct.Pin = IO3_Pin|IO2_Pin;
  GPIO_InitStruct.Mode = GPIO_MODE_INPUT;
  GPIO_InitStruct.Pull = GPIO_NOPULL;
  HAL_GPIO_Init(GPIOB, &GPIO_InitStruct);

  /* EXTI interrupt init*/
  HAL_NVIC_SetPriority(EXTI0_IRQn, 6, 0);
  HAL_NVIC_EnableIRQ(EXTI0_IRQn);

  HAL_NVIC_SetPriority(EXTI2_IRQn, 6, 0);
  HAL_NVIC_EnableIRQ(EXTI2_IRQn);

  HAL_NVIC_SetPriority(EXTI3_IRQn, 6, 0);
  HAL_NVIC_EnableIRQ(EXTI3_IRQn);

}

void Error_Handler(void)
{
  __disable_irq();
  while (1)
  {
  }
}
